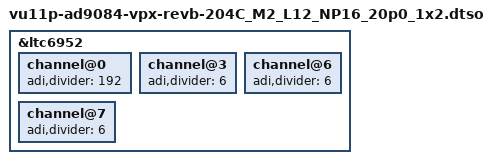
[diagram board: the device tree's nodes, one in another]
// SPDX-License-Identifier: GPL-2.0
/dts-v1/;
/plugin/;

#define DEVICE_PROFILE_NAME     "204C_M2_L12_NP16_20p0_1x2.bin"

#include "vu11p-ad9084-vpx-revb.dtso"

&ltc6952 {
	/* ADF4030 alignment reference at the 27.5 Gbps LEMC rate */
	channel@0 {
		adi,divider = <192>;
	};

	/* JESD reference and device clocks at the lane rate / 66 */
	channel@3 {
		adi,divider = <6>;
	};

	channel@6 {
		adi,divider = <6>;
	};

	channel@7 {
		adi,divider = <6>;
	};
};
